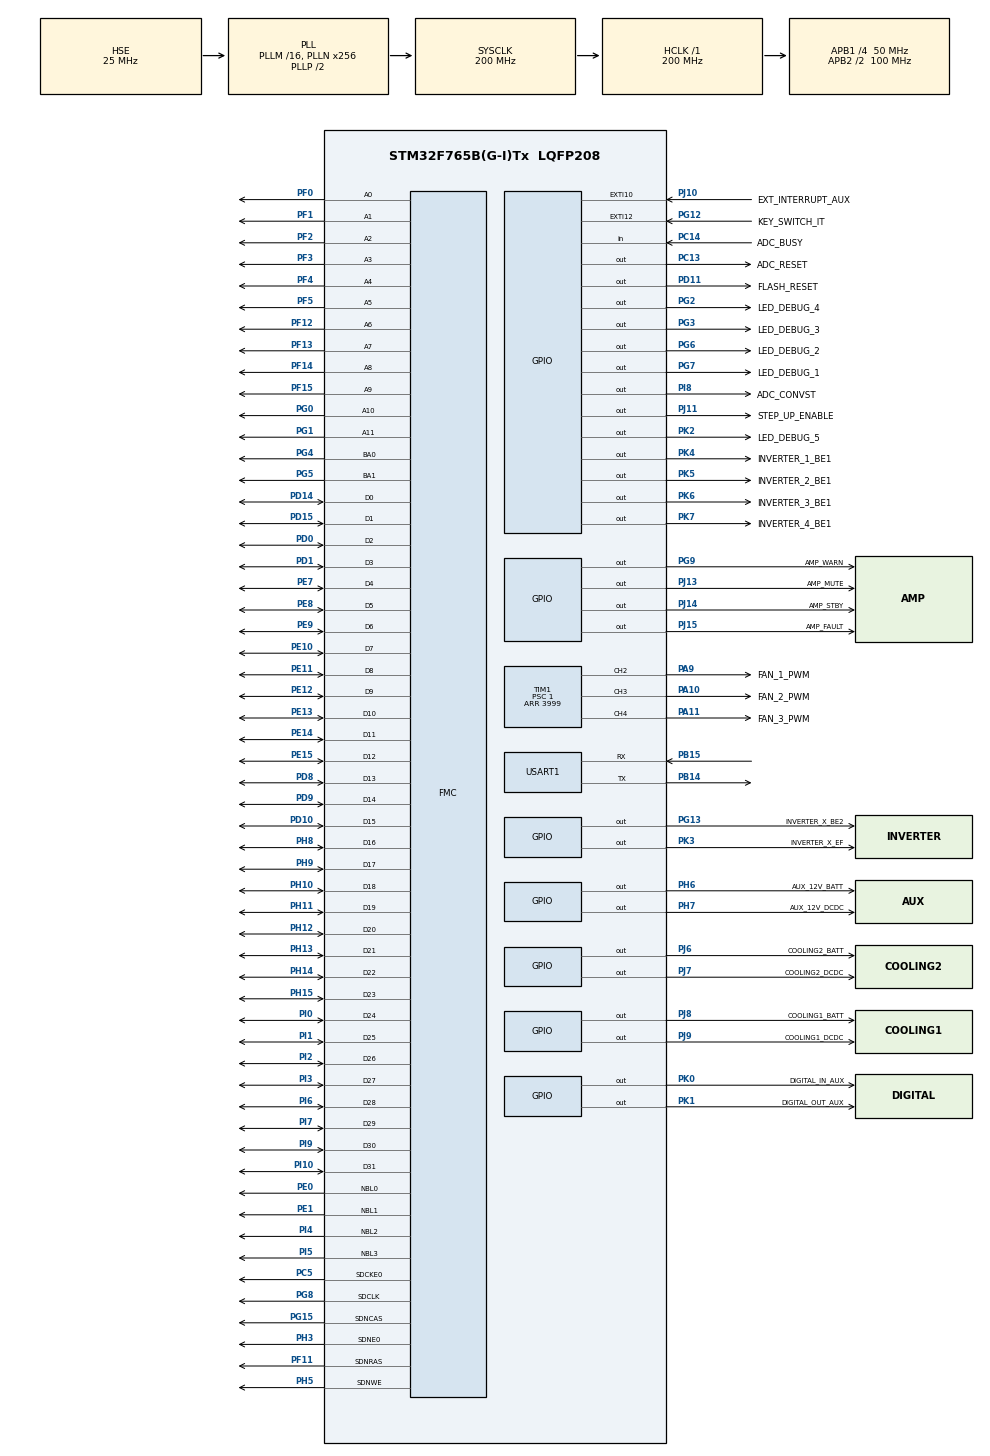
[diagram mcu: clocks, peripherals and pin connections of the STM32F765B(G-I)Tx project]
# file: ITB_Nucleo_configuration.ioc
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CORTEX_M7.ART_ACCLERATOR_ENABLE=1
CORTEX_M7.CPU_DCache=Enabled
CORTEX_M7.CPU_ICache=Enabled
CORTEX_M7.PREFETCH_ENABLE=1
Dma.Request0=USART1_RX
Dma.USART1_RX.0.Direction=DMA_PERIPH_TO_MEMORY
Dma.USART1_RX.0.FIFOMode=DMA_FIFOMODE_DISABLE
Dma.USART1_RX.0.Instance=DMA2_Stream2
Dma.USART1_RX.0.MemDataAlignment=DMA_MDATAALIGN_BYTE
Dma.USART1_RX.0.MemInc=DMA_MINC_ENABLE
Dma.USART1_RX.0.Mode=DMA_NORMAL
Dma.USART1_RX.0.PeriphDataAlignment=DMA_PDATAALIGN_BYTE
Dma.USART1_RX.0.PeriphInc=DMA_PINC_DISABLE
Dma.USART1_RX.0.Priority=DMA_PRIORITY_LOW
FMC.CASLatency1=FMC_SDRAM_CAS_LATENCY_3
FMC.ExitSelfRefreshDelay1=7
FMC.LoadToActiveDelay1=2
FMC.RCDDelay1=2
FMC.RPDelay1=2
FMC.ReadBurst1=FMC_SDRAM_RBURST_ENABLE
FMC.RowCycleDelay1=7
FMC.SDClockPeriod1=FMC_SDRAM_CLOCK_PERIOD_2
FMC.SelfRefreshTime1=4
FMC.WriteRecoveryTime1=3
Mcu.Family=STM32F7
Mcu.Name=STM32F765B(G-I)Tx
Mcu.Package=LQFP208
NVIC.DMA2_Stream2_IRQn=true\:0\:0\:false\:false\:true\:false\:true
NVIC.EXTI15_10_IRQn=true\:7\:0\:true\:false\:true\:true\:true
NVIC.PriorityGroup=NVIC_PRIORITYGROUP_4
NVIC.TIM6_DAC_IRQn=true\:0\:0\:false\:false\:true\:true\:true
NVIC.TIM7_IRQn=true\:0\:0\:false\:false\:true\:false\:true
NVIC.TimeBase=TIM7_IRQn
NVIC.TimeBaseIP=TIM7
NVIC.USART1_IRQn=true\:1\:0\:true\:false\:true\:true\:true
PA10.GPIO_Label=FAN_2_PWM
PA10.Signal=S_TIM1_CH3
PA11.GPIO_Label=FAN_3_PWM
PA11.Signal=S_TIM1_CH4
PA13.Mode=Trace_Asynchronous_SW
PA13.Signal=SYS_JTMS-SWDIO
PA14.Mode=Trace_Asynchronous_SW
PA14.Signal=SYS_JTCK-SWCLK
PA9.GPIO_Label=FAN_1_PWM
PA9.Signal=S_TIM1_CH2
PB12.Signal=CAN2_RX
PB14.Mode=Asynchronous
PB14.Signal=USART1_TX
PB15.Mode=Asynchronous
PB15.Signal=USART1_RX
PB3.Mode=Trace_Asynchronous_SW
PB3.Signal=SYS_JTDO-SWO
PB9.Signal=CAN1_TX
PC13.GPIO_Label=ADC_RESET
PC13.Signal=GPIO_Output
PC14/OSC32_IN.GPIO_Label=ADC_BUSY
PC14/OSC32_IN.Signal=GPIO_Input
PC5.Mode=SdramChipSelect1_1
PC5.Signal=FMC_SDCKE0
PC7.GPIO_Label=PUMP_PWM
PC7.Signal=S_TIM3_CH2
PC8.GPIO_Label=FAN_5_PWM
PC8.Signal=S_TIM8_CH3
PC9.GPIO_Label=FAN_4_PWM
PC9.Signal=S_TIM8_CH4
PD0.Signal=FMC_D2_DA2
PD1.Signal=FMC_D3_DA3
PD10.Signal=FMC_D15_DA15
PD11.GPIO_Label=FLASH_RESET
PD11.PinState=GPIO_PIN_SET
PD11.Signal=GPIO_Output
PD14.Signal=FMC_D0_DA0
PD15.Signal=FMC_D1_DA1
PD8.Signal=FMC_D13_DA13
PD9.Signal=FMC_D14_DA14
PE0.Signal=FMC_NBL0
PE1.Signal=FMC_NBL1
PE10.Signal=FMC_D7_DA7
PE11.Signal=FMC_D8_DA8
PE12.Signal=FMC_D9_DA9
PE13.Signal=FMC_D10_DA10
PE14.Signal=FMC_D11_DA11
PE15.Signal=FMC_D12_DA12
PE7.Signal=FMC_D4_DA4
PE8.Signal=FMC_D5_DA5
PE9.Signal=FMC_D6_DA6
PF0.Signal=FMC_A0
PF1.Signal=FMC_A1
PF11.Signal=FMC_SDNRAS
PF12.Signal=FMC_A6
PF13.Signal=FMC_A7
PF14.Signal=FMC_A8
PF15.Signal=FMC_A9
PF2.Signal=FMC_A2
PF3.Signal=FMC_A3
PF4.Signal=FMC_A4
PF5.Signal=FMC_A5
PF7.Signal=QUADSPI_BK1_IO2
PF8.Signal=QUADSPI_BK1_IO0
PG0.Signal=FMC_A10
PG1.Signal=FMC_A11
PG12.GPIO_Label=KEY_SWITCH_IT
PG12.GPIO_ModeDefaultEXTI=GPIO_MODE_IT_RISING
PG12.Signal=GPXTI12
PG13.GPIO_Label=INVERTER_X_BE2
PG13.Signal=GPIO_Output
PG15.Signal=FMC_SDNCAS
PG2.GPIO_Label=LED_DEBUG_4
PG2.Signal=GPIO_Output
PG3.GPIO_Label=LED_DEBUG_3
PG3.Signal=GPIO_Output
PG4.Signal=FMC_A14_BA0
PG5.Signal=FMC_A15_BA1
PG6.GPIO_Label=LED_DEBUG_2
PG6.Signal=GPIO_Output
PG7.GPIO_Label=LED_DEBUG_1
PG7.Signal=GPIO_Output
PG8.Signal=FMC_SDCLK
PG9.GPIO_Label=AMP_WARN
PG9.Signal=GPIO_Output
PH0/OSC_IN.Mode=HSE-External-Oscillator
PH0/OSC_IN.Signal=RCC_OSC_IN
PH1/OSC_OUT.Mode=HSE-External-Oscillator
PH1/OSC_OUT.Signal=RCC_OSC_OUT
PH10.Signal=FMC_D18
PH11.Signal=FMC_D19
PH12.Signal=FMC_D20
PH13.Signal=FMC_D21
PH14.Signal=FMC_D22
PH15.Signal=FMC_D23
PH3.Mode=SdramChipSelect1_1
PH3.Signal=FMC_SDNE0
PH5.Signal=FMC_SDNWE
PH6.GPIO_Label=AUX_12V_BATT
PH6.Signal=GPIO_Output
PH7.GPIO_Label=AUX_12V_DCDC
PH7.Signal=GPIO_Output
PH8.Signal=FMC_D16
PH9.Signal=FMC_D17
PI0.Signal=FMC_D24
PI1.Signal=FMC_D25
PI10.Signal=FMC_D31
PI2.Signal=FMC_D26
PI3.Signal=FMC_D27
PI4.Signal=FMC_NBL2
PI5.Signal=FMC_NBL3
PI6.Signal=FMC_D28
PI7.Signal=FMC_D29
PI8.GPIO_Label=ADC_CONVST
PI8.Signal=GPIO_Output
PI9.Signal=FMC_D30
PJ10.GPIO_Label=EXT_INTERRUPT_AUX
PJ10.Signal=GPXTI10
PJ11.GPIO_Label=STEP_UP_ENABLE
PJ11.Signal=GPIO_Output
PJ13.GPIO_Label=AMP_MUTE
PJ13.Signal=GPIO_Output
PJ14.GPIO_Label=AMP_STBY
PJ14.Signal=GPIO_Output
PJ15.GPIO_Label=AMP_FAULT
PJ15.Signal=GPIO_Output
PJ6.GPIO_Label=COOLING2_BATT
PJ6.Signal=GPIO_Output
PJ7.GPIO_Label=COOLING2_DCDC
PJ7.Signal=GPIO_Output
PJ8.GPIO_Label=COOLING1_BATT
PJ8.Signal=GPIO_Output
PJ9.GPIO_Label=COOLING1_DCDC
PJ9.Signal=GPIO_Output
PK0.GPIO_Label=DIGITAL_IN_AUX
PK0.Signal=GPIO_Output
PK1.GPIO_Label=DIGITAL_OUT_AUX
PK1.Signal=GPIO_Output
PK2.GPIO_Label=LED_DEBUG_5
PK2.Signal=GPIO_Output
PK3.GPIO_Label=INVERTER_X_EF
PK3.Signal=GPIO_Output
PK4.GPIO_Label=INVERTER_1_BE1
PK4.Signal=GPIO_Output
PK5.GPIO_Label=INVERTER_2_BE1
PK5.Signal=GPIO_Output
PK6.GPIO_Label=INVERTER_3_BE1
PK6.Signal=GPIO_Output
PK7.GPIO_Label=INVERTER_4_BE1
PK7.Signal=GPIO_Output
ProjectManager.HeapSize=0x4000
ProjectManager.StackSize=0x4000
ProjectManager.TargetToolchain=STM32CubeIDE
RCC.AHBFreq_Value=200000000
RCC.APB1CLKDivider=RCC_HCLK_DIV4
RCC.APB1Freq_Value=50000000
RCC.APB1TimFreq_Value=100000000
RCC.APB2CLKDivider=RCC_HCLK_DIV2
RCC.APB2Freq_Value=100000000
RCC.APB2TimFreq_Value=200000000
RCC.CortexFreq_Value=200000000
RCC.HCLKFreq_Value=200000000
RCC.HSE_VALUE=25000000
RCC.HSI_VALUE=16000000
RCC.LSE_VALUE=32768
RCC.PLLI2SN=159
RCC.PLLN=256
RCC.PLLSourceVirtual=RCC_PLLSOURCE_HSE
RCC.SYSCLKFreq_VALUE=200000000
RCC.SYSCLKSource=RCC_SYSCLKSOURCE_PLLCLK
RCC.USBFreq_Value=200000000
RCC.VCOOutputFreq_Value=400000000
SH.FMC_A0.0=FMC_A0,12b-sda1
SH.FMC_A1.0=FMC_A1,12b-sda1
SH.FMC_A10.0=FMC_A10,12b-sda1
SH.FMC_A11.0=FMC_A11,12b-sda1
SH.FMC_A14_BA0.0=FMC_BA0,FourSdramBanks1
SH.FMC_A15_BA1.0=FMC_BA1,FourSdramBanks1
SH.FMC_A2.0=FMC_A2,12b-sda1
SH.FMC_A3.0=FMC_A3,12b-sda1
SH.FMC_A4.0=FMC_A4,12b-sda1
SH.FMC_A5.0=FMC_A5,12b-sda1
SH.FMC_A6.0=FMC_A6,12b-sda1
SH.FMC_A7.0=FMC_A7,12b-sda1
SH.FMC_A8.0=FMC_A8,12b-sda1
SH.FMC_A9.0=FMC_A9,12b-sda1
SH.FMC_D0_DA0.0=FMC_D0,sd-32b-d1
SH.FMC_D10_DA10.0=FMC_D10,sd-32b-d1
SH.FMC_D11_DA11.0=FMC_D11,sd-32b-d1
SH.FMC_D12_DA12.0=FMC_D12,sd-32b-d1
SH.FMC_D13_DA13.0=FMC_D13,sd-32b-d1
SH.FMC_D14_DA14.0=FMC_D14,sd-32b-d1
SH.FMC_D15_DA15.0=FMC_D15,sd-32b-d1
SH.FMC_D16.0=FMC_D16,sd-32b-d1
SH.FMC_D17.0=FMC_D17,sd-32b-d1
SH.FMC_D18.0=FMC_D18,sd-32b-d1
SH.FMC_D19.0=FMC_D19,sd-32b-d1
SH.FMC_D1_DA1.0=FMC_D1,sd-32b-d1
SH.FMC_D20.0=FMC_D20,sd-32b-d1
SH.FMC_D21.0=FMC_D21,sd-32b-d1
SH.FMC_D22.0=FMC_D22,sd-32b-d1
SH.FMC_D23.0=FMC_D23,sd-32b-d1
SH.FMC_D24.0=FMC_D24,sd-32b-d1
SH.FMC_D25.0=FMC_D25,sd-32b-d1
SH.FMC_D26.0=FMC_D26,sd-32b-d1
SH.FMC_D27.0=FMC_D27,sd-32b-d1
SH.FMC_D28.0=FMC_D28,sd-32b-d1
SH.FMC_D29.0=FMC_D29,sd-32b-d1
SH.FMC_D2_DA2.0=FMC_D2,sd-32b-d1
SH.FMC_D30.0=FMC_D30,sd-32b-d1
SH.FMC_D31.0=FMC_D31,sd-32b-d1
SH.FMC_D3_DA3.0=FMC_D3,sd-32b-d1
SH.FMC_D4_DA4.0=FMC_D4,sd-32b-d1
SH.FMC_D5_DA5.0=FMC_D5,sd-32b-d1
SH.FMC_D6_DA6.0=FMC_D6,sd-32b-d1
SH.FMC_D7_DA7.0=FMC_D7,sd-32b-d1
SH.FMC_D8_DA8.0=FMC_D8,sd-32b-d1
SH.FMC_D9_DA9.0=FMC_D9,sd-32b-d1
SH.FMC_NBL0.0=FMC_NBL0,Sd4ByteEnable1
SH.FMC_NBL1.0=FMC_NBL1,Sd4ByteEnable1
SH.FMC_NBL2.0=FMC_NBL2,Sd4ByteEnable1
SH.FMC_NBL3.0=FMC_NBL3,Sd4ByteEnable1
SH.FMC_SDCLK.0=FMC_SDCLK,12b-sda1
SH.FMC_SDNCAS.0=FMC_SDNCAS,12b-sda1
SH.FMC_SDNRAS.0=FMC_SDNRAS,12b-sda1
SH.FMC_SDNWE.0=FMC_SDNWE,12b-sda1
SH.S_TIM1_CH2.0=TIM1_CH2,PWM Generation2 CH2
SH.S_TIM1_CH3.0=TIM1_CH3,PWM Generation3 CH3
SH.S_TIM1_CH4.0=TIM1_CH4,PWM Generation4 CH4
SH.S_TIM3_CH2.0=TIM3_CH2
SH.S_TIM8_CH3.0=TIM8_CH3
SH.S_TIM8_CH4.0=TIM8_CH4
TIM1.Channel-PWM\ Generation2\ CH2=TIM_CHANNEL_2
TIM1.Channel-PWM\ Generation3\ CH3=TIM_CHANNEL_3
TIM1.Channel-PWM\ Generation4\ CH4=TIM_CHANNEL_4
TIM1.Period=3999
TIM1.Prescaler=1
TIM1.Pulse-PWM\ Generation2\ CH2=1999
TIM1.Pulse-PWM\ Generation3\ CH3=1999
TIM1.Pulse-PWM\ Generation4\ CH4=1999
TIM6.Period=1000-1
TIM6.Prescaler=100-1
USART1.VirtualMode-Asynchronous=VM_ASYNC
VP_SYS_VS_tim7.Mode=TIM7
VP_TIM6_VS_ClockSourceINT.Mode=Enable_Timer
board=custom

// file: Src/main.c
/* USER CODE BEGIN Header */
/**
  ******************************************************************************
  * @file           : main.c
  * @brief          : Main program body
  ******************************************************************************
  * @attention
  *
  * <h2><center>&copy; Copyright (c) 2022 STMicroelectronics.
  * All rights reserved.</center></h2>
  *
  * This software component is licensed by ST under BSD 3-Clause license,
  * the "License"; You may not use this file except in compliance with the
  * License. You may obtain a copy of the License at:
  *                        opensource.org/licenses/BSD-3-Clause
  *
  ******************************************************************************
  */
/* USER CODE END Header */
#include "main.h"
#include "dma.h"
#include "tim.h"
#include "usart.h"
#include "gpio.h"
#include "fmc.h"

/* USER CODE BEGIN Includes */
#include "acados_wrapper.h"
#include "acados_solver_dt_model.h"
#include "dt_model_model/dt_model_model.h"
#include "TVModel.h"
#include "usart.h"
/* USER CODE END Includes */

/* USER CODE BEGIN PD */
#define REFRESH_COUNT        1648
#define SDRAM_TIMEOUT                            ((uint32_t)0xFFFF)
#define SDRAM_MODEREG_BURST_LENGTH_1             ((uint16_t)0x0000)
#define SDRAM_MODEREG_BURST_LENGTH_2             ((uint16_t)0x0001)
#define SDRAM_MODEREG_BURST_LENGTH_4             ((uint16_t)0x0002)
#define SDRAM_MODEREG_BURST_LENGTH_8             ((uint16_t)0x0004)
#define SDRAM_MODEREG_BURST_TYPE_SEQUENTIAL      ((uint16_t)0x0000)
#define SDRAM_MODEREG_BURST_TYPE_INTERLEAVED     ((uint16_t)0x0008)
#define SDRAM_MODEREG_CAS_LATENCY_2              ((uint16_t)0x0020)
#define SDRAM_MODEREG_CAS_LATENCY_3              ((uint16_t)0x0030)
#define SDRAM_MODEREG_OPERATING_MODE_STANDARD    ((uint16_t)0x0000)
#define SDRAM_MODEREG_WRITEBURST_MODE_PROGRAMMED ((uint16_t)0x0000)
#define SDRAM_MODEREG_WRITEBURST_MODE_SINGLE     ((uint16_t)0x0200)

void MX_SDRAM_InitEx(void);
static FMC_SDRAM_CommandTypeDef Command;
/* USER CODE END PD */

/* USER CODE BEGIN PV */
extern uint8_t RxData[2*128];
dt_model_solver_capsule *capsule;
uint32_t Dato1;
extern uint32_t Time;
/* USER CODE END PV */

void SystemClock_Config(void);
/* USER CODE BEGIN PFP */
int _gettimeofday( struct timeval *tv, void *tzvp )
{
    uint64_t t = 0;  // get uptime in nanoseconds
    tv->tv_sec = t / 1000000000;  // convert to seconds
    tv->tv_usec = ( t % 1000000000 ) / 1000;  // get remaining microseconds
    return 0;  // return non-zero for error
} // end _gettimeofday()
/* USER CODE END PFP */

int main(void)
{

  /* Enable I-Cache---------------------------------------------------------*/
  SCB_EnableICache();

  /* Enable D-Cache---------------------------------------------------------*/
  SCB_EnableDCache();

  /* MCU Configuration--------------------------------------------------------*/

  /* Reset of all peripherals, Initializes the Flash interface and the Systick. */
  HAL_Init();

  /* Configure the system clock */
  SystemClock_Config();

  /* Initialize all configured peripherals */
  MX_GPIO_Init();
  MX_DMA_Init();
  MX_TIM1_Init();
  MX_FMC_Init();
  MX_USART1_UART_Init();
  MX_TIM6_Init();
  /* USER CODE BEGIN 2 */
    MX_SDRAM_InitEx();
    HAL_Delay(500);

    capsule = dt_model_acados_create_capsule();

    dt_model_acados_create(capsule);

    TVModel_initialize();
    (&huart1)->Instance->CR1|= 0x0010;
    HAL_UART_Receive_IT(&huart1,RxData,2*128);
    HAL_TIM_Base_Start_IT(&htim6);
  /* USER CODE END 2 */

  /* Infinite loop */
  while (1)
  {

  }
}

void SystemClock_Config(void)
{
  RCC_OscInitTypeDef RCC_OscInitStruct = {0};
  RCC_ClkInitTypeDef RCC_ClkInitStruct = {0};
  RCC_PeriphCLKInitTypeDef PeriphClkInitStruct = {0};

  /** Configure the main internal regulator output voltage
  */
  __HAL_RCC_PWR_CLK_ENABLE();
  __HAL_PWR_VOLTAGESCALING_CONFIG(PWR_REGULATOR_VOLTAGE_SCALE1);
  /** Initializes the RCC Oscillators according to the specified parameters
  * in the RCC_OscInitTypeDef structure.
  */
  RCC_OscInitStruct.OscillatorType = RCC_OSCILLATORTYPE_HSE;
  RCC_OscInitStruct.HSEState = RCC_HSE_ON;
  RCC_OscInitStruct.PLL.PLLState = RCC_PLL_ON;
  RCC_OscInitStruct.PLL.PLLSource = RCC_PLLSOURCE_HSE;
  RCC_OscInitStruct.PLL.PLLM = 16;
  RCC_OscInitStruct.PLL.PLLN = 256;
  RCC_OscInitStruct.PLL.PLLP = RCC_PLLP_DIV2;
  RCC_OscInitStruct.PLL.PLLQ = 2;
  if (HAL_RCC_OscConfig(&RCC_OscInitStruct) != HAL_OK)
  {
    Error_Handler();
  }
  /** Activate the Over-Drive mode
  */
  if (HAL_PWREx_EnableOverDrive() != HAL_OK)
  {
    Error_Handler();
  }
  /** Initializes the CPU, AHB and APB buses clocks
  */
  RCC_ClkInitStruct.ClockType = RCC_CLOCKTYPE_HCLK|RCC_CLOCKTYPE_SYSCLK
                              |RCC_CLOCKTYPE_PCLK1|RCC_CLOCKTYPE_PCLK2;
  RCC_ClkInitStruct.SYSCLKSource = RCC_SYSCLKSOURCE_PLLCLK;
  RCC_ClkInitStruct.AHBCLKDivider = RCC_SYSCLK_DIV1;
  RCC_ClkInitStruct.APB1CLKDivider = RCC_HCLK_DIV4;
  RCC_ClkInitStruct.APB2CLKDivider = RCC_HCLK_DIV2;

  if (HAL_RCC_ClockConfig(&RCC_ClkInitStruct, FLASH_LATENCY_6) != HAL_OK)
  {
    Error_Handler();
  }
  PeriphClkInitStruct.PeriphClockSelection = RCC_PERIPHCLK_USART1;
  PeriphClkInitStruct.Usart1ClockSelection = RCC_USART1CLKSOURCE_PCLK2;
  if (HAL_RCCEx_PeriphCLKConfig(&PeriphClkInitStruct) != HAL_OK)
  {
    Error_Handler();
  }
}

/* USER CODE BEGIN 4 */
void MX_SDRAM_InitEx(void)
{
    __IO uint32_t tmpmrd = 0;

    /* Step 1: Configure a clock configuration enable command */
    Command.CommandMode            = FMC_SDRAM_CMD_CLK_ENABLE;
    Command.CommandTarget          =  FMC_SDRAM_CMD_TARGET_BANK1;
    Command.AutoRefreshNumber      = 1;
    Command.ModeRegisterDefinition = 0;

    /* Send the command */
    HAL_SDRAM_SendCommand(&hsdram1, &Command, SDRAM_TIMEOUT);

    /* Step 2: Insert 100 us minimum delay */
    /* Inserted delay is equal to 1 ms due to systick time base unit (ms) */
    HAL_Delay(1);

    /* Step 3: Configure a PALL (precharge all) command */
    Command.CommandMode            = FMC_SDRAM_CMD_PALL;
    Command.CommandTarget          = FMC_SDRAM_CMD_TARGET_BANK1;
    Command.AutoRefreshNumber      = 1;
    Command.ModeRegisterDefinition = 0;

    /* Send the command */
    HAL_SDRAM_SendCommand(&hsdram1, &Command, SDRAM_TIMEOUT);

    /* Step 4: Configure an Auto Refresh command */
    Command.CommandMode            = FMC_SDRAM_CMD_AUTOREFRESH_MODE;
    Command.CommandTarget          = FMC_SDRAM_CMD_TARGET_BANK1;
    Command.AutoRefreshNumber      = 8;
    Command.ModeRegisterDefinition = 0;

    /* Send the command */
    HAL_SDRAM_SendCommand(&hsdram1, &Command, SDRAM_TIMEOUT);

    /* Step 5: Program the external memory mode register */
    tmpmrd = (uint32_t)SDRAM_MODEREG_BURST_LENGTH_1          |\
                     SDRAM_MODEREG_BURST_TYPE_SEQUENTIAL   |\
                     SDRAM_MODEREG_CAS_LATENCY_3           |\
                     SDRAM_MODEREG_OPERATING_MODE_STANDARD |\
                     SDRAM_MODEREG_WRITEBURST_MODE_SINGLE;

    Command.CommandMode            = FMC_SDRAM_CMD_LOAD_MODE;
    Command.CommandTarget          = FMC_SDRAM_CMD_TARGET_BANK1;
    Command.AutoRefreshNumber      = 1;
    Command.ModeRegisterDefinition = tmpmrd;

    /* Send the command */
    HAL_SDRAM_SendCommand(&hsdram1, &Command, SDRAM_TIMEOUT);

    /* Step 6: Set the refresh rate counter */
    /* Set the device refresh rate */
    HAL_SDRAM_ProgramRefreshRate(&hsdram1, REFRESH_COUNT);
}
/* USER CODE END 4 */

void HAL_TIM_PeriodElapsedCallback(TIM_HandleTypeDef *htim)
{
  /* USER CODE BEGIN Callback 0 */
    switch((uint32_t)htim->Instance) {
        case (uint32_t) TIM6:
            Time++;
            break;
    }
  /* USER CODE END Callback 0 */
  if (htim->Instance == TIM7) {
    HAL_IncTick();
  }
}

void Error_Handler(void)
{
}

/************************ (C) COPYRIGHT STMicroelectronics *****END OF FILE****/
